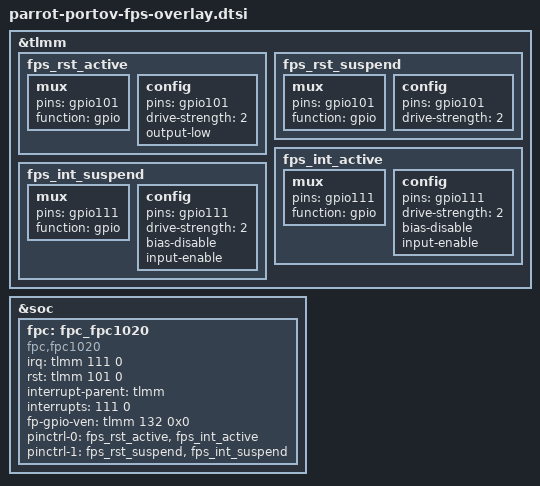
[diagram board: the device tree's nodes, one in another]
&tlmm {
	fps_rst_active: fps_rst_active {
		/* active state */
		mux {
			pins = "gpio101";
			function = "gpio";
		};

		config {
			pins = "gpio101";
			drive-strength = <2>; /* 2 MA */
			output-low;
		};
	};

	fps_rst_suspend: fps_rst_suspend {
		/* sleep state */
		mux {
			pins = "gpio101";
			function = "gpio";
		};

		config {
			pins = "gpio101";
			drive-strength = <2>; /* 2 MA */
		};
	};

	fps_int_active: fps_int_active {
		/* active state */
		mux {
			pins = "gpio111";
			function = "gpio";
		};

		config {
			pins = "gpio111";
			drive-strength = <2>; /* 2 MA */
			bias-disable;
			input-enable;
		};
	};

	fps_int_suspend: fps_int_suspend {
		/* sleep state */
		mux {
			pins = "gpio111";
			function = "gpio";
		};

		config {
			pins = "gpio111";
			drive-strength = <2>; /* 2 MA */
			bias-disable;
			input-enable;
		};
	};
};

&soc {
	fpc: fpc_fpc1020 {
		compatible = "fpc,fpc1020";
		status = "ok";
		irq = <&tlmm 111 0>;
		rst = <&tlmm 101 0>;
		interrupt-parent = <&tlmm>;
		interrupts = <111 0>;
		//rgltr-ctrl-support;
		//fp,vdd-supply=<&L28B>;
		//fp,voltage-range = <3000000 3000000>;
		fp-gpio-ven = <&tlmm 132 0x0>;
		pinctrl-names = "default", "suspend";
		pinctrl-0 = <&fps_rst_active &fps_int_active>;
		pinctrl-1 = <&fps_rst_suspend &fps_int_suspend>;
	};

};
